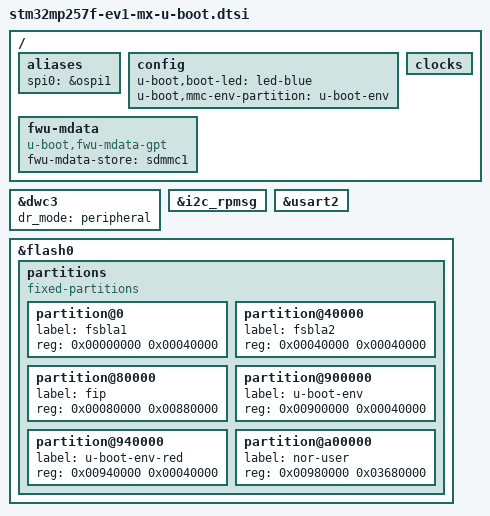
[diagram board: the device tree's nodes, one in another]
// SPDX-License-Identifier: (GPL-2.0-only OR BSD-3-Clause)
/*
 * Copyright (C) 2025, STMicroelectronics - All Rights Reserved
 * Author: STM32CubeMX code generation for STMicroelectronics.
 */

/* For more information on Device Tree configuration, please refer to
 * https://wiki.st.com/stm32mpu/wiki/Category:Device_tree_configuration
 */

#include "stm32mp25-u-boot.dtsi"

/* USER CODE BEGIN includes */
/* USER CODE END includes */

/ {

	/* USER CODE BEGIN root */

	aliases{
		spi0 = &ospi1;
	};

	config{
		u-boot,boot-led = "led-blue";
		u-boot,mmc-env-partition = "u-boot-env";
	};

	fwu-mdata{
		compatible = "u-boot,fwu-mdata-gpt";
		fwu-mdata-store = <&sdmmc1>;
	};
	/* USER CODE END root */

	clocks{

		/* USER CODE BEGIN clocks */
		/* USER CODE END clocks */
	};

}; /*root*/

/* USER CODE BEGIN addons */

&dwc3 {
	dr_mode = "peripheral";
	/delete-node/ port;
};

&i2c_rpmsg {
	/delete-node/ typec@35;
};

&usart2 {
	bootph-all;
};

&flash0 {
	/* Add default partitionning from ST */
        partitions {
                compatible = "fixed-partitions";
                #address-cells = <1>;
                #size-cells = <1>;

                partition@0 {
                        label = "fsbla1";
                        reg = <0x00000000 0x00040000>;
                };
                partition@40000 {
                        label = "fsbla2";
                        reg = <0x00040000 0x00040000>;
                };
                partition@80000 {
                        label = "fip";
                        reg = <0x00080000 0x00880000>;
                };
                partition@900000 {
                        label = "u-boot-env";
                        reg = <0x00900000 0x00040000>;
                };
                partition@940000 {
                        label = "u-boot-env-red";
                        reg = <0x00940000 0x00040000>;
                };
                partition@a00000 {
                        label = "nor-user";
                        reg = <0x00980000 0x03680000>;
                };
        };
};
/* USER CODE END addons */

